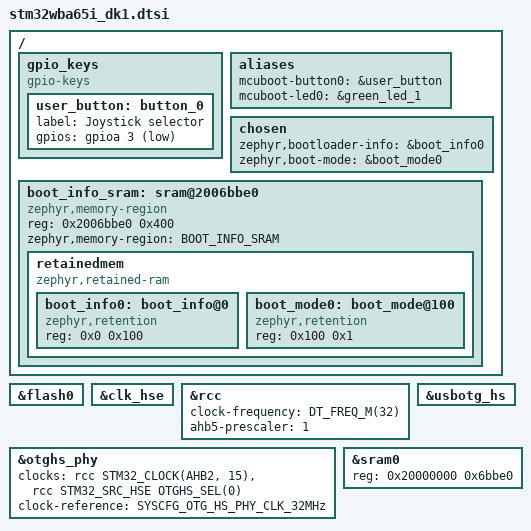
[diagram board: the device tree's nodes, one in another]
/* Delete Zephyr-default partitions before redefining them. */
&flash0 { /delete-node/ partitions; };

/* Enable the OTG HS controller and its internal PHY for the bootloader's
 * UF2 drive. The application's board overlay enables them as well; this
 * keeps the bootloader image self-contained (USBD_DEVICE_DEFINE links
 * against the node's device).
 *
 * USB on STM32WBA requires VOS Range 1. Zephyr selects VOS from HCLK, and
 * 16 MHz keeps it in Range 2, which trips an assertion in udc_stm32. Run
 * SYSCLK from full 32 MHz HSE so VOS is set to Range 1. (The application
 * image gets the same treatment from its board overlay.)
 */
&clk_hse {
	/delete-property/ hse-div2;
};

&rcc {
	clock-frequency = <DT_FREQ_M(32)>;
	ahb5-prescaler = <1>;
};

zephyr_udc0: &usbotg_hs {
	status = "okay";
};

&otghs_phy {
	/* OTG HS clock source is 32 MHz HSE */
	clocks = <&rcc STM32_CLOCK(AHB2, 15)>,
		 <&rcc STM32_SRC_HSE OTGHS_SEL(0)>;
	clock-reference = "SYSCFG_OTG_HS_PHY_CLK_32MHz";
	status = "okay";
};

/* The DK1 has no push button; the joystick's selector (center) button is
 * wired to PA3 with an external pull-up, so it reads active-low.
 */
/ {
	gpio_keys {
		compatible = "gpio-keys";

		user_button: button_0 {
			label = "Joystick selector";
			gpios = <&gpioa 3 GPIO_ACTIVE_LOW>;
		};
	};

	aliases {
		mcuboot-button0 = &user_button;
		mcuboot-led0 = &green_led_1;
	};
};

#include "stm32wba65i_dk1-partitions.dtsi"

/* Bootloader info shared-data area: the last KB of this board's RAM, kept
 * out of the managed RAM so neither image clobbers it. The bootloader
 * writes its boot state here on every boot (BOOT_SHARE_DATA_BOOTINFO ->
 * BLINFO TLVs via boot_write_shared_data()); the application reads the
 * same region to answer the SMP bootloader-info command (RETENTION_
 * BOOTLOADER_INFO_TYPE_MCUBOOT). Carved here because this dtsi applies to
 * both images.
 *
 * A second, one-byte retention cell in the same block backs the boot-mode
 * flag (zephyr,boot-mode): the application sets it to request the
 * bootloader's update mode (reset_to_bootloader() / RunMode.UF2) and the
 * bootloader reads and clears it at boot (io_detect_boot_mode()). SRAM
 * content survives the warm reset that follows the request, which is all a
 * button-less entrance needs; a power cycle simply drops the request.
 */
&sram0 {
	reg = <0x20000000 0x6bbe0>;
};

/ {
	chosen {
		zephyr,bootloader-info = &boot_info0;
		zephyr,boot-mode = &boot_mode0;
	};

	boot_info_sram: sram@2006bbe0 {
		compatible = "zephyr,memory-region", "mmio-sram";
		reg = <0x2006bbe0 0x400>;
		zephyr,memory-region = "BOOT_INFO_SRAM";
		status = "okay";

		retainedmem {
			compatible = "zephyr,retained-ram";
			status = "okay";
			#address-cells = <1>;
			#size-cells = <1>;

			boot_info0: boot_info@0 {
				compatible = "zephyr,retention";
				status = "okay";
				reg = <0x0 0x100>;
			};

			boot_mode0: boot_mode@100 {
				compatible = "zephyr,retention";
				status = "okay";
				reg = <0x100 0x1>;
			};
		};
	};
};
